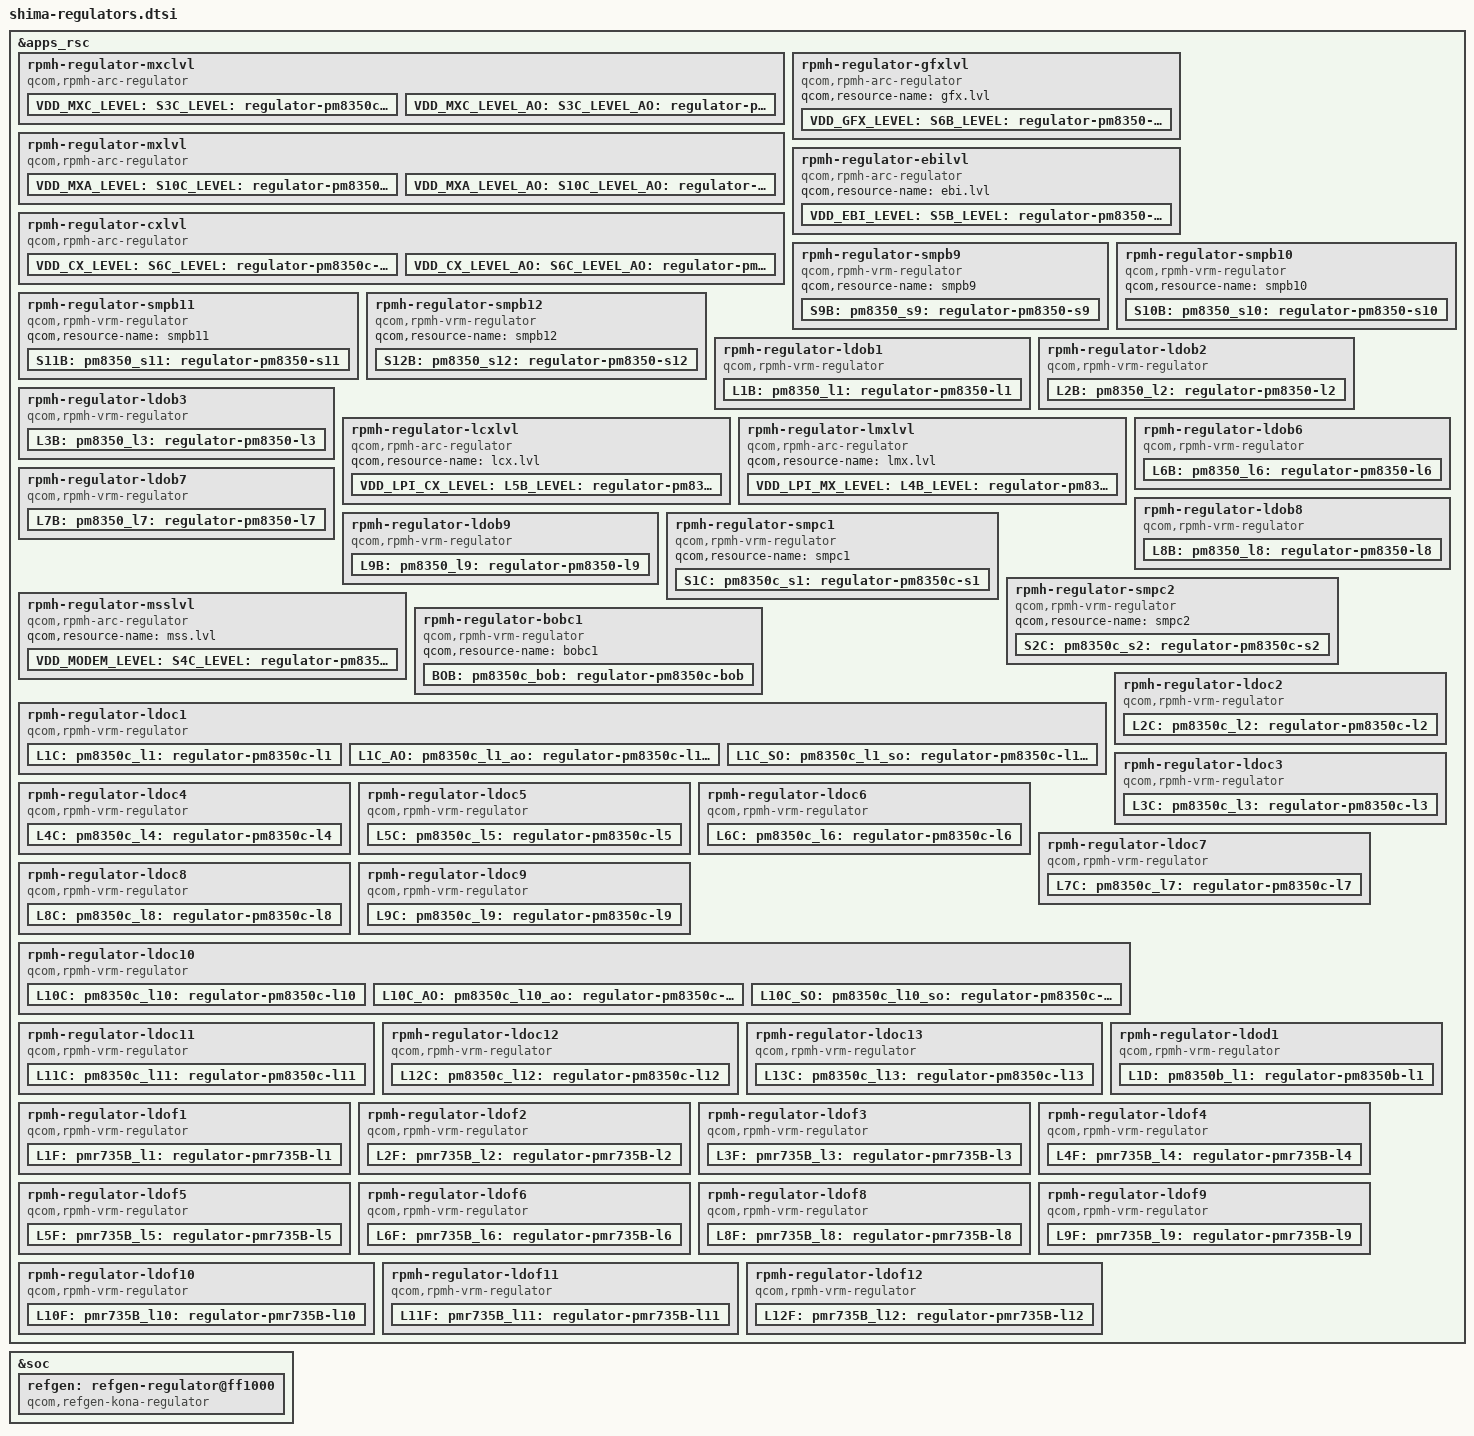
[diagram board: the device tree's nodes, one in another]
#include <dt-bindings/regulator/qcom,rpmh-regulator-levels.h>

&apps_rsc {
	rpmh-regulator-mxclvl {
		compatible = "qcom,rpmh-arc-regulator";
		qcom,resource-name = "mxc.lvl";
		proxy-supply = <&VDD_MXC_LEVEL>;

		VDD_MXC_LEVEL:
		S3C_LEVEL:
		pm8350c_s3_level: regulator-pm8350c-s3-level {
			regulator-name = "pm8350c_s3_level";
			qcom,set = <RPMH_REGULATOR_SET_ALL>;
			regulator-min-microvolt =
				<RPMH_REGULATOR_LEVEL_RETENTION>;
			regulator-max-microvolt = <RPMH_REGULATOR_LEVEL_MAX>;
			qcom,init-voltage-level =
				<RPMH_REGULATOR_LEVEL_TURBO>;
			qcom,proxy-consumer-enable;
			qcom,proxy-consumer-voltage =
				<RPMH_REGULATOR_LEVEL_TURBO
				 RPMH_REGULATOR_LEVEL_MAX>;
		};

		VDD_MXC_LEVEL_AO:
		S3C_LEVEL_AO:
		pm8350c_s3_level_ao: regulator-pm8350c-s3-level-ao {
			regulator-name = "pm8350c_s3_level_ao";
			qcom,set = <RPMH_REGULATOR_SET_ACTIVE>;
			regulator-min-microvolt =
				<RPMH_REGULATOR_LEVEL_RETENTION>;
			regulator-max-microvolt = <RPMH_REGULATOR_LEVEL_MAX>;
			qcom,init-voltage-level =
				<RPMH_REGULATOR_LEVEL_RETENTION>;
		};
	};

	rpmh-regulator-mxlvl {
		compatible = "qcom,rpmh-arc-regulator";
		qcom,resource-name = "mx.lvl";
		proxy-supply = <&VDD_MXA_LEVEL>;

		VDD_MXA_LEVEL:
		S10C_LEVEL:
		pm8350c_s10_level: regulator-pm8350c-s10-level {
			regulator-name = "pm8350c_s10_level";
			qcom,set = <RPMH_REGULATOR_SET_ALL>;
			pm8350c_s10_level-parent-supply = <&VDD_MXC_LEVEL>;
			regulator-min-microvolt =
				<RPMH_REGULATOR_LEVEL_RETENTION>;
			regulator-max-microvolt = <RPMH_REGULATOR_LEVEL_MAX>;
			qcom,init-voltage-level =
				<RPMH_REGULATOR_LEVEL_TURBO>;
			qcom,min-dropout-voltage-level = <(-1)>;
			qcom,proxy-consumer-enable;
			qcom,proxy-consumer-voltage =
				<RPMH_REGULATOR_LEVEL_TURBO
				 RPMH_REGULATOR_LEVEL_MAX>;
		};

		VDD_MXA_LEVEL_AO:
		S10C_LEVEL_AO:
		pm8350c_s10_level_ao: regulator-pm8350c-s10-level-ao {
			regulator-name = "pm8350c_s10_level_ao";
			qcom,set = <RPMH_REGULATOR_SET_ACTIVE>;
			pm8350c_s10_lvl_ao-parent-supply = <&VDD_MXC_LEVEL_AO>;
			regulator-min-microvolt =
				<RPMH_REGULATOR_LEVEL_RETENTION>;
			regulator-max-microvolt = <RPMH_REGULATOR_LEVEL_MAX>;
			qcom,init-voltage-level =
				<RPMH_REGULATOR_LEVEL_RETENTION>;
			qcom,min-dropout-voltage-level = <(-1)>;
		};
	};

	rpmh-regulator-gfxlvl {
		compatible = "qcom,rpmh-arc-regulator";
		qcom,resource-name = "gfx.lvl";
		VDD_GFX_LEVEL:
		S6B_LEVEL:
		pm8350_s6_level: regulator-pm8350-s6-level {
			regulator-name = "pm8350_s6_level";
			qcom,set = <RPMH_REGULATOR_SET_ALL>;
			regulator-min-microvolt =
				<RPMH_REGULATOR_LEVEL_RETENTION>;
			regulator-max-microvolt = <RPMH_REGULATOR_LEVEL_MAX>;
			qcom,init-voltage-level =
				<RPMH_REGULATOR_LEVEL_RETENTION>;
		};
	};

	rpmh-regulator-cxlvl {
		compatible = "qcom,rpmh-arc-regulator";
		qcom,resource-name = "cx.lvl";
		proxy-supply = <&VDD_CX_LEVEL>;

		VDD_CX_LEVEL: S6C_LEVEL:
		pm8350c_s6_level: regulator-pm8350c-s6-level {
			regulator-name = "pm8350c_s6_level";
			qcom,set = <RPMH_REGULATOR_SET_ALL>;
			pm8350c_s6_level-parent-supply = <&VDD_MXA_LEVEL>;
			regulator-min-microvolt =
				<RPMH_REGULATOR_LEVEL_RETENTION>;
			regulator-max-microvolt =
				<RPMH_REGULATOR_LEVEL_MAX>;
			qcom,init-voltage-level =
				<RPMH_REGULATOR_LEVEL_TURBO>;
			qcom,min-dropout-voltage-level = <(-1)>;
			qcom,proxy-consumer-enable;
			qcom,proxy-consumer-voltage =
				<RPMH_REGULATOR_LEVEL_TURBO
				 RPMH_REGULATOR_LEVEL_MAX>;
		};

		VDD_CX_LEVEL_AO: S6C_LEVEL_AO:
		pm8350c_s6_level_ao: regulator-pm8350c-s6-level-ao {
			regulator-name = "pm8350c_s6_level_ao";
			qcom,set = <RPMH_REGULATOR_SET_ACTIVE>;
			vin-supply = <&VDD_MXA_LEVEL_AO>;
			regulator-min-microvolt =
				<RPMH_REGULATOR_LEVEL_RETENTION>;
			regulator-max-microvolt =
				<RPMH_REGULATOR_LEVEL_MAX>;
			qcom,init-voltage-level =
				<RPMH_REGULATOR_LEVEL_RETENTION>;
			qcom,min-dropout-voltage-level = <(-1)>;
		};
	};

	rpmh-regulator-ebilvl {
		compatible = "qcom,rpmh-arc-regulator";
		qcom,resource-name = "ebi.lvl";
		VDD_EBI_LEVEL:
		S5B_LEVEL:
		pm8350_s5_level: regulator-pm8350-s5-level {
			regulator-name = "pm8350_s5_level";
			qcom,set = <RPMH_REGULATOR_SET_ALL>;
			regulator-min-microvolt =
				<RPMH_REGULATOR_LEVEL_RETENTION>;
			regulator-max-microvolt = <RPMH_REGULATOR_LEVEL_MAX>;
			qcom,init-voltage-level =
				<RPMH_REGULATOR_LEVEL_RETENTION>;
		};
	};

	rpmh-regulator-smpb9 {
		compatible = "qcom,rpmh-vrm-regulator";
		qcom,resource-name = "smpb9";
		S9B:
		pm8350_s9: regulator-pm8350-s9 {
			regulator-name = "pm8350_s9";
			qcom,set = <RPMH_REGULATOR_SET_ALL>;
			regulator-min-microvolt = <450000>;
			regulator-max-microvolt = <1500000>;
			qcom,init-voltage = <952000>;
		};
	};

	rpmh-regulator-smpb10 {
		compatible = "qcom,rpmh-vrm-regulator";
		qcom,resource-name = "smpb10";
		S10B:
		pm8350_s10: regulator-pm8350-s10 {
			regulator-name = "pm8350_s10";
			qcom,set = <RPMH_REGULATOR_SET_ALL>;
			regulator-min-microvolt = <1200000>;
			regulator-max-microvolt = <2040000>;
			qcom,init-voltage = <1800000>;
		};
	};

	rpmh-regulator-smpb11 {
		compatible = "qcom,rpmh-vrm-regulator";
		qcom,resource-name = "smpb11";
		S11B:
		pm8350_s11: regulator-pm8350-s11 {
			regulator-name = "pm8350_s11";
			qcom,set = <RPMH_REGULATOR_SET_ALL>;
			regulator-min-microvolt = <1700000>;
			regulator-max-microvolt = <2040000>;
			qcom,init-voltage = <1880000>;
		};
	};

	rpmh-regulator-smpb12 {
		compatible = "qcom,rpmh-vrm-regulator";
		qcom,resource-name = "smpb12";
		S12B:
		pm8350_s12: regulator-pm8350-s12 {
			regulator-name = "pm8350_s12";
			qcom,set = <RPMH_REGULATOR_SET_ALL>;
			regulator-min-microvolt = <382000>;
			regulator-max-microvolt = <1654000>;
			qcom,init-voltage = <1256000>;
		};
	};

	rpmh-regulator-ldob1 {
		compatible = "qcom,rpmh-vrm-regulator";
		qcom,resource-name = "ldob1";
		qcom,regulator-type = "pmic5-ldo";
		qcom,supported-modes =
			<RPMH_REGULATOR_MODE_LPM
			RPMH_REGULATOR_MODE_HPM>;
		qcom,mode-threshold-currents = <0 30000>;
		L1B:
		pm8350_l1: regulator-pm8350-l1 {
			regulator-name = "pm8350_l1";
			qcom,set = <RPMH_REGULATOR_SET_ALL>;
			regulator-min-microvolt = <825000>;
			regulator-max-microvolt = <925000>;
			qcom,init-voltage = <912000>;
			qcom,init-mode = <RPMH_REGULATOR_MODE_HPM>;
		};
	};

	rpmh-regulator-ldob2 {
		compatible = "qcom,rpmh-vrm-regulator";
		qcom,resource-name = "ldob2";
		qcom,regulator-type = "pmic5-ldo";
		qcom,supported-modes =
			<RPMH_REGULATOR_MODE_LPM
			RPMH_REGULATOR_MODE_HPM>;
		qcom,mode-threshold-currents = <0 30000>;
		L2B:
		pm8350_l2: regulator-pm8350-l2 {
			regulator-name = "pm8350_l2";
			qcom,set = <RPMH_REGULATOR_SET_ALL>;
			regulator-min-microvolt = <2700000>;
			regulator-max-microvolt = <3544000>;
			qcom,init-voltage = <3072000>;
			qcom,init-mode = <RPMH_REGULATOR_MODE_HPM>;
		};
	};

	rpmh-regulator-ldob3 {
		compatible = "qcom,rpmh-vrm-regulator";
		qcom,resource-name = "ldob3";
		qcom,regulator-type = "pmic5-ldo";
		qcom,supported-modes =
			<RPMH_REGULATOR_MODE_LPM
			RPMH_REGULATOR_MODE_HPM>;
		qcom,mode-threshold-currents = <0 30000>;
		L3B:
		pm8350_l3: regulator-pm8350-l3 {
			regulator-name = "pm8350_l3";
			qcom,set = <RPMH_REGULATOR_SET_ALL>;
			regulator-min-microvolt = <470000>;
			regulator-max-microvolt = <910000>;
			qcom,init-voltage = <504000>;
			qcom,init-mode = <RPMH_REGULATOR_MODE_HPM>;
		};
	};

	rpmh-regulator-lcxlvl {
		compatible = "qcom,rpmh-arc-regulator";
		qcom,resource-name = "lcx.lvl";
		VDD_LPI_CX_LEVEL:
		L5B_LEVEL:
		pm8350_l5_level: regulator-pm8350-l5-level {
			regulator-name = "pm8350_l5_level";
			qcom,set = <RPMH_REGULATOR_SET_ALL>;
			regulator-min-microvolt =
				<RPMH_REGULATOR_LEVEL_RETENTION>;
			regulator-max-microvolt = <RPMH_REGULATOR_LEVEL_MAX>;
			qcom,init-voltage-level =
				<RPMH_REGULATOR_LEVEL_RETENTION>;
		};
	};

	rpmh-regulator-lmxlvl {
		compatible = "qcom,rpmh-arc-regulator";
		qcom,resource-name = "lmx.lvl";
		VDD_LPI_MX_LEVEL:
		L4B_LEVEL:
		pm8350_l4_level: regulator-pm8350-l4-level {
			regulator-name = "pm8350_l4_level";
			qcom,set = <RPMH_REGULATOR_SET_ALL>;
			regulator-min-microvolt =
				<RPMH_REGULATOR_LEVEL_RETENTION>;
			regulator-max-microvolt = <RPMH_REGULATOR_LEVEL_MAX>;
			qcom,init-voltage-level =
				<RPMH_REGULATOR_LEVEL_RETENTION>;
		};
	};


	rpmh-regulator-ldob6 {
		compatible = "qcom,rpmh-vrm-regulator";
		qcom,resource-name = "ldob6";
		qcom,regulator-type = "pmic5-ldo";
		qcom,supported-modes =
			<RPMH_REGULATOR_MODE_LPM
			RPMH_REGULATOR_MODE_HPM>;
		qcom,mode-threshold-currents = <0 30000>;
		L6B:
		pm8350_l6: regulator-pm8350-l6 {
			regulator-name = "pm8350_l6";
			qcom,set = <RPMH_REGULATOR_SET_ALL>;
			regulator-min-microvolt = <1140000>;
			regulator-max-microvolt = <1260000>;
			qcom,init-voltage = <1200000>;
			qcom,init-mode = <RPMH_REGULATOR_MODE_HPM>;
		};
	};

	rpmh-regulator-ldob7 {
		compatible = "qcom,rpmh-vrm-regulator";
		qcom,resource-name = "ldob7";
		qcom,regulator-type = "pmic5-ldo";
		qcom,supported-modes =
			<RPMH_REGULATOR_MODE_LPM
			RPMH_REGULATOR_MODE_HPM>;
		qcom,mode-threshold-currents = <0 30000>;
		L7B:
		pm8350_l7: regulator-pm8350-l7 {
			regulator-name = "pm8350_l7";
			qcom,set = <RPMH_REGULATOR_SET_ALL>;
			regulator-min-microvolt = <2400000>;
			regulator-max-microvolt = <3544000>;
			qcom,init-voltage = <2952000>;
			qcom,init-mode = <RPMH_REGULATOR_MODE_HPM>;
		};
	};

	rpmh-regulator-ldob8 {
		compatible = "qcom,rpmh-vrm-regulator";
		qcom,resource-name = "ldob8";
		qcom,regulator-type = "pmic5-ldo";
		qcom,supported-modes =
			<RPMH_REGULATOR_MODE_LPM
			RPMH_REGULATOR_MODE_HPM>;
		qcom,mode-threshold-currents = <0 30000>;
		L8B:
		pm8350_l8: regulator-pm8350-l8 {
			regulator-name = "pm8350_l8";
			qcom,set = <RPMH_REGULATOR_SET_ALL>;
			regulator-min-microvolt = <870000>;
			regulator-max-microvolt = <970000>;
			qcom,init-voltage = <904000>;
			qcom,init-mode = <RPMH_REGULATOR_MODE_HPM>;
		};
	};

	rpmh-regulator-ldob9 {
		compatible = "qcom,rpmh-vrm-regulator";
		qcom,resource-name = "ldob9";
		qcom,regulator-type = "pmic5-ldo";
		qcom,supported-modes =
			<RPMH_REGULATOR_MODE_RET
			 RPMH_REGULATOR_MODE_LPM
			 RPMH_REGULATOR_MODE_HPM>;
		qcom,mode-threshold-currents = <0 10000 30000>;
		L9B:
		pm8350_l9: regulator-pm8350-l9 {
			regulator-name = "pm8350_l9";
			qcom,set = <RPMH_REGULATOR_SET_ALL>;
			regulator-min-microvolt = <1080000>;
			regulator-max-microvolt = <1304000>;
			qcom,init-voltage = <1200000>;
			qcom,init-mode = <RPMH_REGULATOR_MODE_HPM>;
		};
	};

	rpmh-regulator-smpc1 {
		compatible = "qcom,rpmh-vrm-regulator";
		qcom,resource-name = "smpc1";
		S1C:
		pm8350c_s1: regulator-pm8350c-s1 {
			regulator-name = "pm8350c_s1";
			qcom,set = <RPMH_REGULATOR_SET_ALL>;
			regulator-min-microvolt = <2190000>;
			regulator-max-microvolt = <2200000>;
			qcom,init-voltage = <2190000>;
		};
	};

	rpmh-regulator-smpc2 {
		compatible = "qcom,rpmh-vrm-regulator";
		qcom,resource-name = "smpc2";
		S2C:
		pm8350c_s2: regulator-pm8350c-s2 {
			regulator-name = "pm8350c_s2";
			qcom,set = <RPMH_REGULATOR_SET_ALL>;
			regulator-min-microvolt = <722000>;
			regulator-max-microvolt = <950000>;
			qcom,init-voltage = <722000>;
		};
	};

	rpmh-regulator-msslvl {
		compatible = "qcom,rpmh-arc-regulator";
		qcom,resource-name = "mss.lvl";
		VDD_MODEM_LEVEL:
		S4C_LEVEL:
		pm8350c_s4_level: regulator-pm8350c-s4-level {
			regulator-name = "pm8350c_s4_level";
			qcom,set = <RPMH_REGULATOR_SET_ALL>;
			regulator-min-microvolt =
				<RPMH_REGULATOR_LEVEL_RETENTION>;
			regulator-max-microvolt = <RPMH_REGULATOR_LEVEL_MAX>;
			qcom,init-voltage-level =
				<RPMH_REGULATOR_LEVEL_RETENTION>;
		};
	};

	rpmh-regulator-bobc1 {
		compatible = "qcom,rpmh-vrm-regulator";
		qcom,resource-name = "bobc1";
		BOB: pm8350c_bob: regulator-pm8350c-bob {
			regulator-name = "pm8350c_bob";
			qcom,set = <RPMH_REGULATOR_SET_ALL>;
			regulator-min-microvolt = <3008000>;
			regulator-max-microvolt = <3960000>;
			qcom,init-voltage = <3296000>;
		};
	};

	rpmh-regulator-ldoc1 {
		compatible = "qcom,rpmh-vrm-regulator";
		qcom,resource-name = "ldoc1";
		qcom,regulator-type = "pmic5-ldo";
		qcom,supported-modes =
			<RPMH_REGULATOR_MODE_LPM
			RPMH_REGULATOR_MODE_HPM>;
		qcom,mode-threshold-currents = <0 30000>;
		L1C:
		pm8350c_l1: regulator-pm8350c-l1 {
			regulator-name = "pm8350c_l1";
			qcom,set = <RPMH_REGULATOR_SET_ALL>;
			regulator-min-microvolt = <1620000>;
			regulator-max-microvolt = <1980000>;
			qcom,init-voltage = <1800000>;
			qcom,init-mode = <RPMH_REGULATOR_MODE_HPM>;
		};

		L1C_AO: pm8350c_l1_ao: regulator-pm8350c-l1-ao {
			regulator-name = "pm8350c_l1_ao";
			qcom,set = <RPMH_REGULATOR_SET_ACTIVE>;
			regulator-min-microvolt = <1620000>;
			regulator-max-microvolt = <1980000>;
			qcom,init-voltage = <1800000>;
			qcom,init-mode = <RPMH_REGULATOR_MODE_LPM>;
		};

		L1C_SO: pm8350c_l1_so: regulator-pm8350c-l1-so {
			regulator-name = "pm8350c_l1_so";
			qcom,set = <RPMH_REGULATOR_SET_SLEEP>;
			regulator-min-microvolt = <1620000>;
			regulator-max-microvolt = <1980000>;
			qcom,init-voltage = <1800000>;
			qcom,init-mode = <RPMH_REGULATOR_MODE_LPM>;
			qcom,init-enable = <0>;
		};
	};

	rpmh-regulator-ldoc2 {
		compatible = "qcom,rpmh-vrm-regulator";
		qcom,resource-name = "ldoc2";
		qcom,regulator-type = "pmic5-ldo";
		qcom,supported-modes =
			<RPMH_REGULATOR_MODE_LPM
			RPMH_REGULATOR_MODE_HPM>;
		qcom,mode-threshold-currents = <0 30000>;
		L2C:
		pm8350c_l2: regulator-pm8350c-l2 {
			regulator-name = "pm8350c_l2";
			qcom,set = <RPMH_REGULATOR_SET_ALL>;
			regulator-min-microvolt = <1620000>;
			regulator-max-microvolt = <1980000>;
			qcom,init-voltage = <1620000>;
			qcom,init-mode = <RPMH_REGULATOR_MODE_HPM>;
		};
	};

	rpmh-regulator-ldoc3 {
		compatible = "qcom,rpmh-vrm-regulator";
		qcom,resource-name = "ldoc3";
		qcom,regulator-type = "pmic5-ldo";
		qcom,supported-modes =
			<RPMH_REGULATOR_MODE_LPM
			RPMH_REGULATOR_MODE_HPM>;
		qcom,mode-threshold-currents = <0 30000>;
		L3C:
		pm8350c_l3: regulator-pm8350c-l3 {
			regulator-name = "pm8350c_l3";
			qcom,set = <RPMH_REGULATOR_SET_ALL>;
			regulator-min-microvolt = <2700000>;
			regulator-max-microvolt = <3540000>;
			qcom,init-voltage = <2700000>;
			qcom,init-mode = <RPMH_REGULATOR_MODE_HPM>;
		};
	};

	rpmh-regulator-ldoc4 {
		compatible = "qcom,rpmh-vrm-regulator";
		qcom,resource-name = "ldoc4";
		qcom,regulator-type = "pmic5-ldo";
		qcom,supported-modes =
			<RPMH_REGULATOR_MODE_LPM
			RPMH_REGULATOR_MODE_HPM>;
		qcom,mode-threshold-currents = <0 30000>;
		L4C:
		pm8350c_l4: regulator-pm8350c-l4 {
			regulator-name = "pm8350c_l4";
			qcom,set = <RPMH_REGULATOR_SET_ALL>;
			regulator-min-microvolt = <1620000>;
			regulator-max-microvolt = <3300000>;
			qcom,init-voltage = <1620000>;
			qcom,init-mode = <RPMH_REGULATOR_MODE_HPM>;
		};
	};

	rpmh-regulator-ldoc5 {
		compatible = "qcom,rpmh-vrm-regulator";
		qcom,resource-name = "ldoc5";
		qcom,regulator-type = "pmic5-ldo";
		qcom,supported-modes =
			<RPMH_REGULATOR_MODE_LPM
			RPMH_REGULATOR_MODE_HPM>;
		qcom,mode-threshold-currents = <0 30000>;
		L5C:
		pm8350c_l5: regulator-pm8350c-l5 {
			regulator-name = "pm8350c_l5";
			qcom,set = <RPMH_REGULATOR_SET_ALL>;
			regulator-min-microvolt = <1620000>;
			regulator-max-microvolt = <3300000>;
			qcom,init-voltage = <1620000>;
			qcom,init-mode = <RPMH_REGULATOR_MODE_HPM>;
		};
	};

	rpmh-regulator-ldoc6 {
		compatible = "qcom,rpmh-vrm-regulator";
		qcom,resource-name = "ldoc6";
		qcom,regulator-type = "pmic5-ldo";
		qcom,supported-modes =
			<RPMH_REGULATOR_MODE_LPM
			RPMH_REGULATOR_MODE_HPM>;
		qcom,mode-threshold-currents = <0 30000>;
		L6C:
		pm8350c_l6: regulator-pm8350c-l6 {
			regulator-name = "pm8350c_l6";
			qcom,set = <RPMH_REGULATOR_SET_ALL>;
			regulator-min-microvolt = <1650000>;
			regulator-max-microvolt = <3544000>;
			qcom,init-voltage = <2960000>;
			qcom,init-mode = <RPMH_REGULATOR_MODE_HPM>;
		};
	};

	rpmh-regulator-ldoc7 {
		compatible = "qcom,rpmh-vrm-regulator";
		qcom,resource-name = "ldoc7";
		qcom,regulator-type = "pmic5-ldo";
		qcom,supported-modes =
			<RPMH_REGULATOR_MODE_LPM
			RPMH_REGULATOR_MODE_HPM>;
		qcom,mode-threshold-currents = <0 30000>;
		L7C:
		pm8350c_l7: regulator-pm8350c-l7 {
			regulator-name = "pm8350c_l7";
			qcom,set = <RPMH_REGULATOR_SET_ALL>;
			regulator-min-microvolt = <3000000>;
			regulator-max-microvolt = <3544000>;
			qcom,init-voltage = <3000000>;
			qcom,init-mode = <RPMH_REGULATOR_MODE_HPM>;
		};
	};

	rpmh-regulator-ldoc8 {
		compatible = "qcom,rpmh-vrm-regulator";
		qcom,resource-name = "ldoc8";
		qcom,regulator-type = "pmic5-ldo";
		qcom,supported-modes =
			<RPMH_REGULATOR_MODE_LPM
			RPMH_REGULATOR_MODE_HPM>;
		qcom,mode-threshold-currents = <0 30000>;
		L8C:
		pm8350c_l8: regulator-pm8350c-l8 {
			regulator-name = "pm8350c_l8";
			qcom,set = <RPMH_REGULATOR_SET_ALL>;
			regulator-min-microvolt = <1620000>;
			regulator-max-microvolt = <2000000>;
			qcom,init-voltage = <1620000>;
			qcom,init-mode = <RPMH_REGULATOR_MODE_HPM>;
		};
	};

	rpmh-regulator-ldoc9 {
		compatible = "qcom,rpmh-vrm-regulator";
		qcom,resource-name = "ldoc9";
		qcom,regulator-type = "pmic5-ldo";
		qcom,supported-modes =
			<RPMH_REGULATOR_MODE_LPM
			RPMH_REGULATOR_MODE_HPM>;
		qcom,mode-threshold-currents = <0 30000>;
		L9C:
		pm8350c_l9: regulator-pm8350c-l9 {
			regulator-name = "pm8350c_l9";
			qcom,set = <RPMH_REGULATOR_SET_ALL>;
			regulator-min-microvolt = <2700000>;
			regulator-max-microvolt = <3544000>;
			qcom,init-voltage = <2960000>;
			qcom,init-mode = <RPMH_REGULATOR_MODE_HPM>;
		};
	};

	rpmh-regulator-ldoc10 {
		compatible = "qcom,rpmh-vrm-regulator";
		qcom,resource-name = "ldoc10";
		qcom,regulator-type = "pmic5-ldo";
		qcom,supported-modes =
			<RPMH_REGULATOR_MODE_LPM
			RPMH_REGULATOR_MODE_HPM>;
		qcom,mode-threshold-currents = <0 30000>;
		L10C:
		pm8350c_l10: regulator-pm8350c-l10 {
			regulator-name = "pm8350c_l10";
			qcom,set = <RPMH_REGULATOR_SET_ALL>;
			regulator-min-microvolt = <720000>;
			regulator-max-microvolt = <1050000>;
			qcom,init-voltage = <880000>;
			qcom,init-mode = <RPMH_REGULATOR_MODE_HPM>;
		};

		L10C_AO:
		pm8350c_l10_ao: regulator-pm8350c-l10-ao {
			regulator-name = "pm8350c_l10_ao";
			qcom,set = <RPMH_REGULATOR_SET_ACTIVE>;
			regulator-min-microvolt = <720000>;
			regulator-max-microvolt = <1050000>;
			qcom,init-voltage = <880000>;
			qcom,init-mode = <RPMH_REGULATOR_MODE_LPM>;
		};

		L10C_SO:
		pm8350c_l10_so: regulator-pm8350c-l10-so {
			regulator-name = "pm8350c_l10_so";
			qcom,set = <RPMH_REGULATOR_SET_SLEEP>;
			regulator-min-microvolt = <720000>;
			regulator-max-microvolt = <1050000>;
			qcom,init-voltage = <880000>;
			qcom,init-mode = <RPMH_REGULATOR_MODE_LPM>;
			qcom,init-enable = <0>;
		};
	};

	rpmh-regulator-ldoc11 {
		compatible = "qcom,rpmh-vrm-regulator";
		qcom,resource-name = "ldoc11";
		qcom,regulator-type = "pmic5-ldo";
		qcom,supported-modes =
			<RPMH_REGULATOR_MODE_LPM
			RPMH_REGULATOR_MODE_HPM>;
		qcom,mode-threshold-currents = <0 30000>;
		L11C:
		pm8350c_l11: regulator-pm8350c-l11 {
			regulator-name = "pm8350c_l11";
			qcom,set = <RPMH_REGULATOR_SET_ALL>;
			regulator-min-microvolt = <1650000>;
			regulator-max-microvolt = <3544000>;
			qcom,init-voltage = <1650000>;
			qcom,init-mode = <RPMH_REGULATOR_MODE_HPM>;
		};
	};

	rpmh-regulator-ldoc12 {
		compatible = "qcom,rpmh-vrm-regulator";
		qcom,resource-name = "ldoc12";
		qcom,regulator-type = "pmic5-ldo";
		qcom,supported-modes =
			<RPMH_REGULATOR_MODE_LPM
			RPMH_REGULATOR_MODE_HPM>;
		qcom,mode-threshold-currents = <0 30000>;
		proxy-supply = <&pm8350c_l12>;
		L12C:
		pm8350c_l12: regulator-pm8350c-l12 {
			regulator-name = "pm8350c_l12";
			qcom,set = <RPMH_REGULATOR_SET_ALL>;
			regulator-min-microvolt = <1920000>;
			regulator-max-microvolt = <1980000>;
			qcom,init-voltage = <1920000>;
			qcom,init-mode = <RPMH_REGULATOR_MODE_HPM>;
			qcom,proxy-consumer-enable;
			qcom,proxy-consumer-current = <60700>;
		};
	};

	rpmh-regulator-ldoc13 {
		compatible = "qcom,rpmh-vrm-regulator";
		qcom,resource-name = "ldoc13";
		qcom,regulator-type = "pmic5-ldo";
		qcom,supported-modes =
			<RPMH_REGULATOR_MODE_LPM
			RPMH_REGULATOR_MODE_HPM>;
		qcom,mode-threshold-currents = <0 30000>;
		proxy-supply = <&pm8350c_l13>;
		L13C:
		pm8350c_l13: regulator-pm8350c-l13 {
			regulator-name = "pm8350c_l13";
			qcom,set = <RPMH_REGULATOR_SET_ALL>;
			regulator-min-microvolt = <2700000>;
			regulator-max-microvolt = <3544000>;
			qcom,init-voltage = <2700000>;
			qcom,init-mode = <RPMH_REGULATOR_MODE_HPM>;
			qcom,proxy-consumer-enable;
			qcom,proxy-consumer-current = <30000>;
		};
	};

	rpmh-regulator-ldod1 {
		compatible = "qcom,rpmh-vrm-regulator";
		qcom,resource-name = "ldod1";
		qcom,regulator-type = "pmic5-ldo";
		qcom,supported-modes =
			<RPMH_REGULATOR_MODE_LPM
			 RPMH_REGULATOR_MODE_HPM>;
		qcom,mode-threshold-currents = <0 30000>;
		L1D: pm8350b_l1: regulator-pm8350b-l1 {
			regulator-name = "pm8350b_l1";
			qcom,set = <RPMH_REGULATOR_SET_ALL>;
			regulator-min-microvolt = <1200000>;
			regulator-max-microvolt = <1200000>;
			qcom,init-voltage = <1200000>;
			qcom,init-mode = <RPMH_REGULATOR_MODE_HPM>;
		};
	};

	rpmh-regulator-ldof1 {
		compatible = "qcom,rpmh-vrm-regulator";
		qcom,resource-name = "ldof1";
		qcom,regulator-type = "pmic5-ldo";
		qcom,supported-modes =
			<RPMH_REGULATOR_MODE_LPM
			RPMH_REGULATOR_MODE_HPM>;
		qcom,mode-threshold-currents = <0 30000>;
		L1F:
		pmr735B_l1: regulator-pmr735B-l1 {
			regulator-name = "pmr735B_l1";
			qcom,set = <RPMH_REGULATOR_SET_ALL>;
			regulator-min-microvolt = <880000>;
			regulator-max-microvolt = <1140000>;
			qcom,init-voltage = <880000>;
			qcom,init-mode = <RPMH_REGULATOR_MODE_HPM>;
		};
	};

	rpmh-regulator-ldof2 {
		compatible = "qcom,rpmh-vrm-regulator";
		qcom,resource-name = "ldof2";
		qcom,regulator-type = "pmic5-ldo";
		qcom,supported-modes =
			<RPMH_REGULATOR_MODE_LPM
			RPMH_REGULATOR_MODE_HPM>;
		qcom,mode-threshold-currents = <0 30000>;
		L2F:
		pmr735B_l2: regulator-pmr735B-l2 {
			regulator-name = "pmr735B_l2";
			qcom,set = <RPMH_REGULATOR_SET_ALL>;
			regulator-min-microvolt = <1080000>;
			regulator-max-microvolt = <1304000>;
			qcom,init-voltage = <1080000>;
			qcom,init-mode = <RPMH_REGULATOR_MODE_HPM>;
		};
	};

	rpmh-regulator-ldof3 {
		compatible = "qcom,rpmh-vrm-regulator";
		qcom,resource-name = "ldof3";
		qcom,regulator-type = "pmic5-ldo";
		qcom,supported-modes =
			<RPMH_REGULATOR_MODE_LPM
			RPMH_REGULATOR_MODE_HPM>;
		qcom,mode-threshold-currents = <0 30000>;
		L3F:
		pmr735B_l3: regulator-pmr735B-l3 {
			regulator-name = "pmr735B_l3";
			qcom,set = <RPMH_REGULATOR_SET_ALL>;
			regulator-min-microvolt = <866000>;
			regulator-max-microvolt = <939000>;
			qcom,init-voltage = <866000>;
			qcom,init-mode = <RPMH_REGULATOR_MODE_HPM>;
		};
	};

	rpmh-regulator-ldof4 {
		compatible = "qcom,rpmh-vrm-regulator";
		qcom,resource-name = "ldof4";
		qcom,regulator-type = "pmic5-ldo";
		qcom,supported-modes =
			<RPMH_REGULATOR_MODE_LPM
			RPMH_REGULATOR_MODE_HPM>;
		qcom,mode-threshold-currents = <0 30000>;
		L4F:
		pmr735B_l4: regulator-pmr735B-l4 {
			regulator-name = "pmr735B_l4";
			qcom,set = <RPMH_REGULATOR_SET_ALL>;
			regulator-min-microvolt = <1620000>;
			regulator-max-microvolt = <2000000>;
			qcom,init-voltage = <1620000>;
			qcom,init-mode = <RPMH_REGULATOR_MODE_HPM>;
		};
	};

	rpmh-regulator-ldof5 {
		compatible = "qcom,rpmh-vrm-regulator";
		qcom,resource-name = "ldof5";
		qcom,regulator-type = "pmic5-ldo";
		qcom,supported-modes =
			<RPMH_REGULATOR_MODE_LPM
			RPMH_REGULATOR_MODE_HPM>;
		qcom,mode-threshold-currents = <0 30000>;
		L5F:
		pmr735B_l5: regulator-pmr735B-l5 {
			regulator-name = "pmr735B_l5";
			qcom,set = <RPMH_REGULATOR_SET_ALL>;
			regulator-min-microvolt = <756000>;
			regulator-max-microvolt = <824000>;
			qcom,init-voltage = <756000>;
			qcom,init-mode = <RPMH_REGULATOR_MODE_HPM>;
		};
	};

	rpmh-regulator-ldof6 {
		compatible = "qcom,rpmh-vrm-regulator";
		qcom,resource-name = "ldof6";
		qcom,regulator-type = "pmic5-ldo";
		qcom,supported-modes =
			<RPMH_REGULATOR_MODE_LPM
			RPMH_REGULATOR_MODE_HPM>;
		qcom,mode-threshold-currents = <0 30000>;
		L6F:
		pmr735B_l6: regulator-pmr735B-l6 {
			regulator-name = "pmr735B_l6";
			qcom,set = <RPMH_REGULATOR_SET_ALL>;
			regulator-min-microvolt = <720000>;
			regulator-max-microvolt = <824000>;
			qcom,init-voltage = <720000>;
			qcom,init-mode = <RPMH_REGULATOR_MODE_HPM>;
		};
	};

	rpmh-regulator-ldof8 {
		compatible = "qcom,rpmh-vrm-regulator";
		qcom,resource-name = "ldof8";
		qcom,regulator-type = "pmic5-ldo";
		qcom,supported-modes =
			<RPMH_REGULATOR_MODE_LPM
			RPMH_REGULATOR_MODE_HPM>;
		qcom,mode-threshold-currents = <0 30000>;
		L8F:
		pmr735B_l8: regulator-pmr735B-l8 {
			regulator-name = "pmr735B_l8";
			qcom,set = <RPMH_REGULATOR_SET_ALL>;
			regulator-min-microvolt = <1139000>;
			regulator-max-microvolt = <1236000>;
			qcom,init-voltage = <1139000>;
			qcom,init-mode = <RPMH_REGULATOR_MODE_HPM>;
		};
	};

	rpmh-regulator-ldof9 {
		compatible = "qcom,rpmh-vrm-regulator";
		qcom,resource-name = "ldof9";
		qcom,regulator-type = "pmic5-ldo";
		qcom,supported-modes =
			<RPMH_REGULATOR_MODE_LPM
			RPMH_REGULATOR_MODE_HPM>;
		qcom,mode-threshold-currents = <0 30000>;
		L9F:
		pmr735B_l9: regulator-pmr735B-l9 {
			regulator-name = "pmr735B_l9";
			qcom,set = <RPMH_REGULATOR_SET_ALL>;
			regulator-min-microvolt = <765000>;
			regulator-max-microvolt = <1020000>;
			qcom,init-voltage = <765000>;
			qcom,init-mode = <RPMH_REGULATOR_MODE_HPM>;
		};
	};

	rpmh-regulator-ldof10 {
		compatible = "qcom,rpmh-vrm-regulator";
		qcom,resource-name = "ldof10";
		qcom,regulator-type = "pmic5-ldo";
		qcom,supported-modes =
			<RPMH_REGULATOR_MODE_LPM
			RPMH_REGULATOR_MODE_HPM>;
		qcom,mode-threshold-currents = <0 30000>;
		L10F:
		pmr735B_l10: regulator-pmr735B-l10 {
			regulator-name = "pmr735B_l10";
			qcom,set = <RPMH_REGULATOR_SET_ALL>;
			regulator-min-microvolt = <1700000>;
			regulator-max-microvolt = <1900000>;
			qcom,init-voltage = <1700000>;
			qcom,init-mode = <RPMH_REGULATOR_MODE_HPM>;
		};
	};

	rpmh-regulator-ldof11 {
		compatible = "qcom,rpmh-vrm-regulator";
		qcom,resource-name = "ldof11";
		qcom,regulator-type = "pmic5-ldo";
		qcom,supported-modes =
			<RPMH_REGULATOR_MODE_LPM
			RPMH_REGULATOR_MODE_HPM>;
		qcom,mode-threshold-currents = <0 30000>;
		L11F:
		pmr735B_l11: regulator-pmr735B-l11 {
			regulator-name = "pmr735B_l11";
			qcom,set = <RPMH_REGULATOR_SET_ALL>;
			regulator-min-microvolt = <652000>;
			regulator-max-microvolt = <800000>;
			qcom,init-voltage = <652000>;
			qcom,init-mode = <RPMH_REGULATOR_MODE_HPM>;
		};
	};

	rpmh-regulator-ldof12 {
		compatible = "qcom,rpmh-vrm-regulator";
		qcom,resource-name = "ldof12";
		qcom,regulator-type = "pmic5-ldo";
		qcom,supported-modes =
			<RPMH_REGULATOR_MODE_LPM
			RPMH_REGULATOR_MODE_HPM>;
		qcom,mode-threshold-currents = <0 30000>;
		L12F:
		pmr735B_l12: regulator-pmr735B-l12 {
			regulator-name = "pmr735B_l12";
			qcom,set = <RPMH_REGULATOR_SET_ALL>;
			regulator-min-microvolt = <760000>;
			regulator-max-microvolt = <855000>;
			qcom,init-voltage = <760000>;
			qcom,init-mode = <RPMH_REGULATOR_MODE_HPM>;
		};
	};
};

&soc {
	refgen: refgen-regulator@ff1000 {
		compatible = "qcom,refgen-kona-regulator";
		reg = <0xff1000 0x84>;
		regulator-name = "refgen";
		proxy-supply = <&refgen>;
		qcom,proxy-consumer-enable;
		regulator-enable-ramp-delay = <5>;
	};
};
